# SAMA7G54D2GN4 register map
Vendor: Microchip Technology; Series: SAMA7G5; File version: 0
Registers are 32-bit, read-write, reset 0x0 unless marked. A register's access mark holds for its fields unless they carry their own. Offsets are from the block's base; [hi:lo] are bit positions; lines under a group give offsets from that group; {n}, {i} and the like mark numbered series.

## SHDWC — Shutdown Controller
Base 0xE001D010
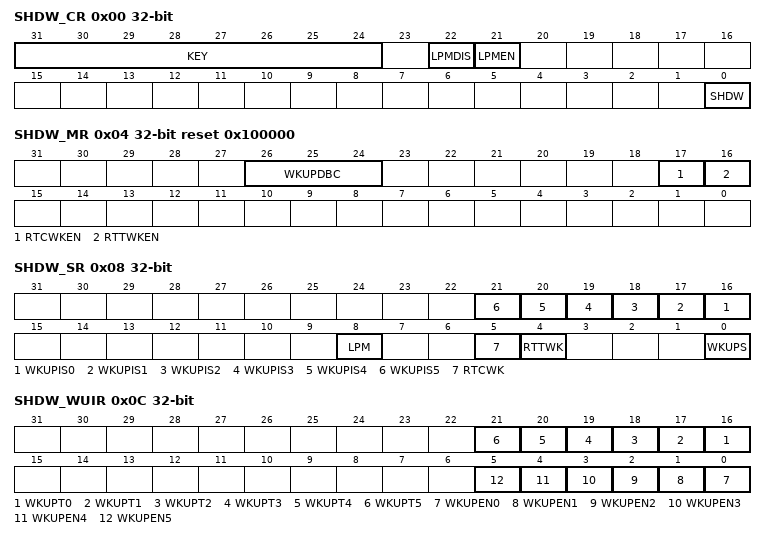
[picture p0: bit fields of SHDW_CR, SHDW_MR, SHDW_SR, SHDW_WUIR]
0x00 SHDW_CR wo — Control Register
  [31:24] KEY — Password
    165=PASSWD (Writing any other value in this field aborts the write operation.)
  [22] LPMDIS — LPM Pad Disable
    0=No effect; 1=The LPM pad is set low (external regulator is set in standard powering state)
  [21] LPMEN — LPM Pad Enable
    0=No effect; 1=The LPM pad is set high (external regulator is set in special powering state)
  [0] SHDW — Shutdown Command
    0=No effect; 1=If KEY value is correct, asserts the SHDN pin
0x04 SHDW_MR reset 0x100000 — Mode Register
  [26:24] WKUPDBC — Wake-up Inputs Debouncer Period
    0=IMMEDIATE (Immediate, no debouncing, detected active at least on one MD_SLCK edge.); 1=3_SLCK (PIOBUx shall be in its active state for at least 3 MD_SLCK periods); 2=32_SLCK (PIOBUx shall be in its active state for at least 32 MD_SLCK periods); 3=512_SLCK (PIOBUx shall be in its active state for at least 512 MD_SLCK periods); 4=4096_SLCK (PIOBUx shall be in its active state for at least 4,096 MD_SLCK periods); 5=32768_SLCK (PIOBUx shall be in its active state for at least 32,768 MD_SLCK periods)
  [17] RTCWKEN — Real-time Clock Wake-up Enable
    0=The RTC Alarm signal has no effect on the SHDWC; 1=The RTC Alarm signal forces the de-assertion of the SHDN pin
  [16] RTTWKEN — Real-time Timer Wake-up Enable
    0=The RTT Alarm signal has no effect on the SHDWC; 1=The RTT Alarm signal forces the de-assertion of the SHDN pin
0x08 SHDW_SR ro — Status Register
  [n+16] WKUPIS{n} (n=0..5) — Wake-up 0 to 5 Input Status
    0=DISABLE (The corresponding wake-up input is disabled, or was inactive at the time the debouncer triggered a wake-up event.); 1=ENABLE (The corresponding wake-up input was active at the time the debouncer triggered a wake-up event.)
  [8] LPM — Low-Power Mode Pad Status
    0=The LPM pad is currently set to 0; 1=The LPM pad is currently set to 1
  [5] RTCWK — Real-time Clock Wake-up
    0=No wake-up alarm from the RTC occurred since the last read of SHDW_SR; 1=At least one wake-up alarm from the RTC occurred since the last read of SHDW_SR
  [4] RTTWK — Real-time Timer Wake-up
    0=No wake-up alarm from the RTT occurred since the last read of SHDW_SR; 1=At least one wake-up alarm from the RTT occurred since the last read of SHDW_SR
  [0] WKUPS — Wake-up Status
    0=NO (No wake-up due to the assertion of the wake-up pins has occurred since the last read of SHDW_SR.); 1=PRESENT (At least one wake-up due to the assertion of the wake-up pins has occurred since the last read of SHDW_SR.)
0x0C SHDW_WUIR — Wake-up Inputs Register
  [n+16] WKUPT{n} (n=0..5) — Wake-up 0 to 5 Input Type
    0=LOW (A falling edge followed by a low level on the corresponding wake-up input, for a period defined by WKUPDBC, forces wake-up of the core power supply.); 1=HIGH (A rising edge followed by a high level on the corresponding wake-up input, for a period defined by WKUPDBC, forces wake-up of the core power supply.)
  [n] WKUPEN{n} (n=0..5) — Wake-up 0 to 5 Input Enable
    0=DISABLE (The corresponding wake-up input has no wake-up effect.); 1=ENABLE (The corresponding wake-up input forces wake-up of the core power supply.)

## SYSCWP — System Controller Write Protection
Base 0xE001D0DC
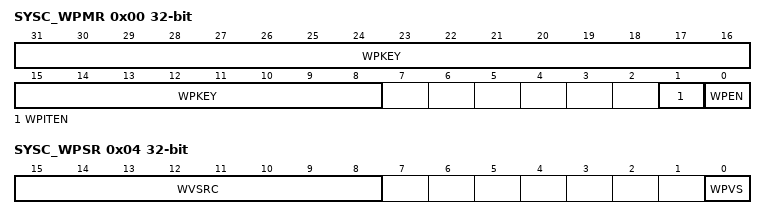
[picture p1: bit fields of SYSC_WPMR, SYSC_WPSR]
0x00 SYSC_WPMR — Write Protection Mode Register
  [31:8] WPKEY — Write Protection Key
    0x535943=PASSWD (Writing any other value in this field aborts the write operation of the WPEN and WPITEN bits. Always reads as 0.)
  [1] WPITEN — Write Protection RTC Interrupt Enable
    0=Disables the write protection of the RTC_IER/RTC_IDR configuration registers if WPKEY corresponds to 0x535943 ('SYC' in ASCII); 1=Enables the write protection of the RTC_IER/RTC_IDR configuration registers if WPKEY corresponds to 0x535943 ('SYC' in ASCII)
  [0] WPEN — Write Protection Enable
    0=Disables the write protection of the configuration registers if WPKEY corresponds to 0x535943 ('SYC' in ASCII); 1=Enables the write protection of the configuration registers if WPKEY corresponds to 0x535943 ('SYC' in ASCII)
0x04 SYSC_WPSR ro — Write Protection Status Register
  [15:8] WVSRC — Write Violation Source
  [0] WPVS — Write Protection Register Violation Status
    0=No write protection violation has occurred since the last read of SYSC_WPSR; 1=A write protection violation has occurred since the last read of SYSC_WPSR. The associated violation is reported into field WVSRC.

## TZAESBASC — AES Bridge Address Space Controller
Base 0xE2000000
{0x0+8i} TZAESBASC_RID[{i}] (i=0..7) group
  0x00 RBAR — Region Base Address
    [31:0] BASE
  0x04 RTAR — Region Top Address
    [31:0] TOP
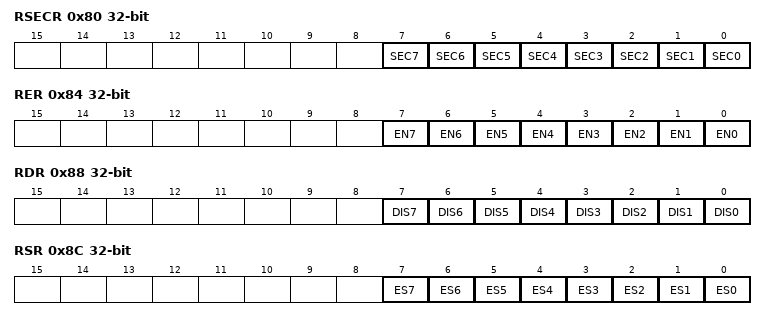
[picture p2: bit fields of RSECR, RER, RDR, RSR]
0x80 RSECR — Region Security
  [all] fields
    0=Region x is secure; 1=Region x is non-secure
  [n] SEC{n} (n=0..7) — Region {n} Security
0x84 RER wo — Region Enable
  [all] fields
    0=No effect; 1=Enables the corresponding region
  [n] EN{n} (n=0..7) — Region {n} Enable
0x88 RDR wo — Region Disable
  [all] fields
    0=No effect; 1=Disables the corresponding region
  [n] DIS{n} (n=0..7) — Region {n} Disable
0x8C RSR ro — Region Status
  [all] fields
    0=The corresponding region is disabled; 1=The corresponding region is enabled
  [n] ES{n} (n=0..7) — Region {n} Enable Status
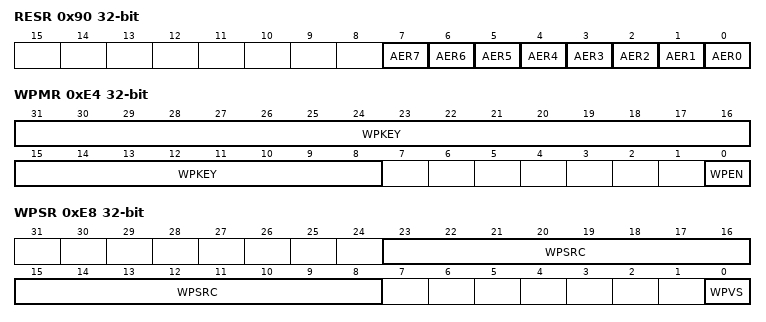
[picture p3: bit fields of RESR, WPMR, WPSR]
0x90 RESR ro — Region Error Status
  [all] fields
    0=No region x address error has occurred; 1=A region x address error has occurred since the last read of the Region Error Status register
  [n] AER{n} (n=0..7) — Region {n} Address Error
0x94 RSSR ro — Region Synchronization Status
  [0] SYNC
    0=Synchronization of the region configuration is done; 1=A region configuration is in progress
0xE4 WPMR — Write Protection Mode Register
  [31:8] WPKEY — Write Protection Key
    0x415343=PASSWD (Writing any other value in this field aborts the write operation of the WPEN bit. Always reads at 0.)
  [0] WPEN — Write Protection Enable
    0=Disables the write protection if WPKEY corresponds to 0x415343 ('ASC' in ASCII); 1=Enables the write protection. All accesses to configuration registers are canceled and generate an error in the TZAESBASC_WPSR register.
0xE8 WPSR ro — Write Protection Status Register
  [23:8] WPSRC — Write Protection Source
  [0] WPVS — Write Protection Violation Status
    0=No write protection violation has occurred since the last read of IP_Acronym_WPSR; 1=A write protection violation has occurred since the last read of IP_Acronym_WPSR. If this violation is an unauthorized attempt to write a protected register, the associated violation is reported into field WPSRC.

## TZPM — System Interconnect and Security
Base 0xE0010000
0x04 KEY — TrustZone Peripheral Manager Key
  [31:0] TZPMKEY — Key preventing TZPM_PIDRx registers to be modified unintentionally by software
    0x12AC4B5D=PASSWD (Writing any other value in this field aborts the write operation of the TZPM_PIDRx Registers. Always reads as 0.)
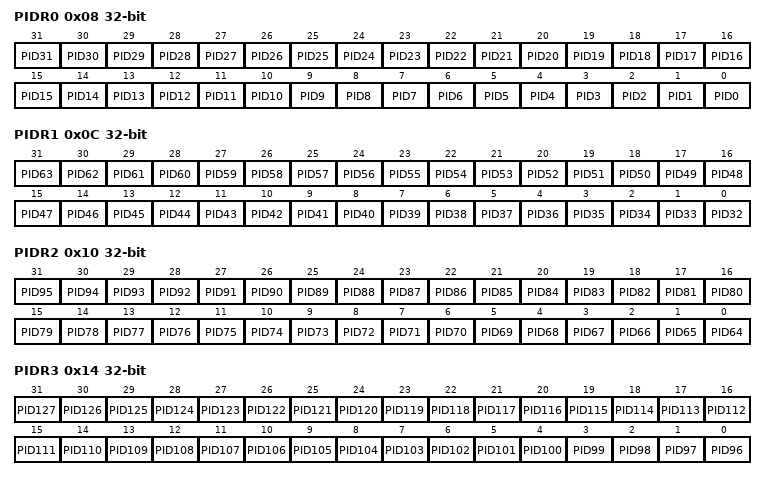
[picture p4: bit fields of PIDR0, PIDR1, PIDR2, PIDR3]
0x08 PIDR0 — TrustZone Peripheral Manager Peripheral ID Register 0
  [all] fields
    0=Secure Accesses only; 1=Non Secure Accesses are allowed
  [n] PID{n} (n=0..31) — Peripheral ID {n} Security
0x0C PIDR1 — TrustZone Peripheral Manager Peripheral ID Register 1
  [all] fields
    0=Secure Accesses only; 1=Non Secure Accesses are allowed
  [n-32] PID{n} (n=32..63) — Peripheral ID {n} Security
0x10 PIDR2 — TrustZone Peripheral Manager Peripheral ID Register 2
  [all] fields
    0=Secure Accesses only; 1=Non Secure Accesses are allowed
  [n-64] PID{n} (n=64..95) — Peripheral ID {n} Security
0x14 PIDR3 — TrustZone Peripheral Manager Peripheral ID Register 3
  [all] fields
    0=Secure Accesses only; 1=Non Secure Accesses are allowed
  [n-96] PID{n} (n=96..127) — Peripheral ID {n} Security
